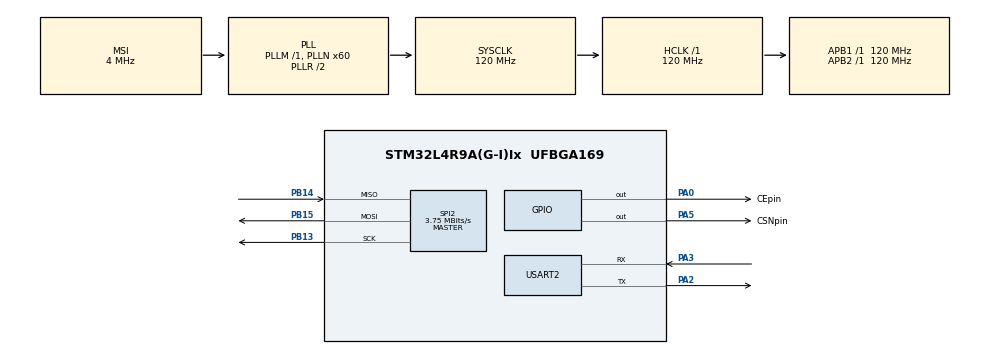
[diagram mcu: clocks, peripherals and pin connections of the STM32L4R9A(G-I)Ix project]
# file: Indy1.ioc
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Mcu.Family=STM32L4
Mcu.Name=STM32L4R9A(G-I)Ix
Mcu.Package=UFBGA169
NVIC.PriorityGroup=NVIC_PRIORITYGROUP_4
PA0.GPIO_Label=CEpin
PA0.Signal=GPIO_Output
PA2.Mode=Asynchronous
PA2.Signal=USART2_TX
PA3.Mode=Asynchronous
PA3.Signal=USART2_RX
PA5.GPIO_Label=CSNpin
PA5.Signal=GPIO_Output
PB13.Mode=Full_Duplex_Master
PB13.Signal=SPI2_SCK
PB14.Mode=Full_Duplex_Master
PB14.Signal=SPI2_MISO
PB15.Mode=Full_Duplex_Master
PB15.Signal=SPI2_MOSI
ProjectManager.HeapSize=0x200
ProjectManager.StackSize=0x400
ProjectManager.TargetToolchain=STM32CubeIDE
RCC.ADCFreq_Value=32000000
RCC.AHBFreq_Value=120000000
RCC.APB1Freq_Value=120000000
RCC.APB1TimFreq_Value=120000000
RCC.APB2Freq_Value=120000000
RCC.APB2TimFreq_Value=120000000
RCC.CK48CLockSelection=RCC_USBCLKSOURCE_HSI48
RCC.CortexFreq_Value=120000000
RCC.HCLKFreq_Value=120000000
RCC.HSE_VALUE=16000000
RCC.HSI48_VALUE=48000000
RCC.HSI_VALUE=16000000
RCC.LSE_VALUE=32768
RCC.MSI_VALUE=4000000
RCC.PLLDSINDIV=32
RCC.PLLN=60
RCC.PLLP=RCC_PLLP_DIV5
RCC.PLLSAI1N=16
RCC.SYSCLKFreq_VALUE=120000000
RCC.SYSCLKSource=RCC_SYSCLKSOURCE_PLLCLK
RCC.USBFreq_Value=48000000
RCC.VCOOutputFreq_Value=240000000
SPI2.BaudRatePrescaler=SPI_BAUDRATEPRESCALER_32
SPI2.CalculateBaudRate=3.75 MBits/s
SPI2.DataSize=SPI_DATASIZE_8BIT
SPI2.Direction=SPI_DIRECTION_2LINES
SPI2.Mode=SPI_MODE_MASTER
SPI2.VirtualType=VM_MASTER
STMicroelectronics.X-CUBE-TOUCHGFX.4.13.0.ApplicationCcGraphicsJjApplication=TouchGFXOoGenerator
USART2.VirtualMode-Asynchronous=VM_ASYNC
board=STM32L4R9I-DISCO

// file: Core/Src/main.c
/* USER CODE BEGIN Header */
/**
  ******************************************************************************
  * @file           : main.c
  * @brief          : Main program body
  ******************************************************************************
  * @attention
  *
  * <h2><center>&copy; Copyright (c) 2020 STMicroelectronics.
  * All rights reserved.</center></h2>
  *
  * This software component is licensed by ST under BSD 3-Clause license,
  * the "License"; You may not use this file except in compliance with the
  * License. You may obtain a copy of the License at:
  *                        opensource.org/licenses/BSD-3-Clause
  *
  ******************************************************************************
  */
/* USER CODE END Header */

#include "main.h"

/* USER CODE BEGIN Includes */
#include "MY_NRF24.h"
#include "Mousejack.h"
#include "stm32l4xx_hal.h"
/* USER CODE END Includes */

/* USER CODE BEGIN PD */
uint8_t myTxData[13] = "Hello World\r\n";
/* USER CODE END PD */

void SystemClock_Config(void);
static void MX_GPIO_Init(void);
static void MX_SPI2_Init(void);
static void MX_USART2_UART_Init(void);

int main(void)
{

  /* MCU Configuration--------------------------------------------------------*/

  /* Reset of all peripherals, Initializes the Flash interface and the Systick. */
  HAL_Init();

  /* Configure the system clock */
  SystemClock_Config();

  /* Initialize all configured peripherals */
  MX_GPIO_Init();
  MX_SPI2_Init();
  MX_USART2_UART_Init();
  /* USER CODE BEGIN 2 */

  //NRF24_begin(CEpin_GPIO_Port, CSNpin_Pin, CEpin_Pin, hspi2);
  nrf24_DebugUART_Init(huart2);
  while(1){
	  loop();
  }
  /* USER CODE END 2 */

  /* Infinite loop */
  /* USER CODE BEGIN WHILE */
  if(NRF24_Check()){
	  //Success!
	  printRadioSettings();
  }//end if
  else{
	  //Failure
	  while(1){};
  }//end else*/
  while (1)
  {
    /* USER CODE END WHILE */

    /* USER CODE BEGIN 3 */
//	  char msg[100];
//	  sprintf(msg, "Hello, world please work\r\n");
	  //HAL_UART_Transmit(&nrf24_huart, (uint8_t *)uartTxBuf, strlen(uartTxBuf), 10);
//	  HAL_UART_Transmit(&huart2, (uint8_t *)msg, strlen(msg), 10);
//	  HAL_Delay(300);

  }
  /* USER CODE END 3 */
}

void SystemClock_Config(void)
{
  RCC_OscInitTypeDef RCC_OscInitStruct = {0};
  RCC_ClkInitTypeDef RCC_ClkInitStruct = {0};
  RCC_PeriphCLKInitTypeDef PeriphClkInit = {0};

  /** Configure the main internal regulator output voltage
  */
  if (HAL_PWREx_ControlVoltageScaling(PWR_REGULATOR_VOLTAGE_SCALE1_BOOST) != HAL_OK)
  {
    Error_Handler();
  }
  /** Initializes the CPU, AHB and APB busses clocks
  */
  RCC_OscInitStruct.OscillatorType = RCC_OSCILLATORTYPE_MSI;
  RCC_OscInitStruct.MSIState = RCC_MSI_ON;
  RCC_OscInitStruct.MSICalibrationValue = 0;
  RCC_OscInitStruct.MSIClockRange = RCC_MSIRANGE_6;
  RCC_OscInitStruct.PLL.PLLState = RCC_PLL_ON;
  RCC_OscInitStruct.PLL.PLLSource = RCC_PLLSOURCE_MSI;
  RCC_OscInitStruct.PLL.PLLM = 1;
  RCC_OscInitStruct.PLL.PLLN = 60;
  RCC_OscInitStruct.PLL.PLLP = RCC_PLLP_DIV5;
  RCC_OscInitStruct.PLL.PLLQ = RCC_PLLQ_DIV2;
  RCC_OscInitStruct.PLL.PLLR = RCC_PLLR_DIV2;
  if (HAL_RCC_OscConfig(&RCC_OscInitStruct) != HAL_OK)
  {
    Error_Handler();
  }
  /** Initializes the CPU, AHB and APB busses clocks
  */
  RCC_ClkInitStruct.ClockType = RCC_CLOCKTYPE_HCLK|RCC_CLOCKTYPE_SYSCLK
                              |RCC_CLOCKTYPE_PCLK1|RCC_CLOCKTYPE_PCLK2;
  RCC_ClkInitStruct.SYSCLKSource = RCC_SYSCLKSOURCE_PLLCLK;
  RCC_ClkInitStruct.AHBCLKDivider = RCC_SYSCLK_DIV1;
  RCC_ClkInitStruct.APB1CLKDivider = RCC_HCLK_DIV1;
  RCC_ClkInitStruct.APB2CLKDivider = RCC_HCLK_DIV1;

  if (HAL_RCC_ClockConfig(&RCC_ClkInitStruct, FLASH_LATENCY_5) != HAL_OK)
  {
    Error_Handler();
  }
  PeriphClkInit.PeriphClockSelection = RCC_PERIPHCLK_USART2;
  PeriphClkInit.Usart2ClockSelection = RCC_USART2CLKSOURCE_PCLK1;
  if (HAL_RCCEx_PeriphCLKConfig(&PeriphClkInit) != HAL_OK)
  {
    Error_Handler();
  }
}

static void MX_SPI2_Init(void)
{

  /* SPI2 parameter configuration*/
  hspi2.Instance = SPI2;
  hspi2.Init.Mode = SPI_MODE_MASTER;
  hspi2.Init.Direction = SPI_DIRECTION_2LINES;
  hspi2.Init.DataSize = SPI_DATASIZE_8BIT;
  hspi2.Init.CLKPolarity = SPI_POLARITY_LOW;
  hspi2.Init.CLKPhase = SPI_PHASE_1EDGE;
  hspi2.Init.NSS = SPI_NSS_SOFT;
  hspi2.Init.BaudRatePrescaler = SPI_BAUDRATEPRESCALER_32;
  hspi2.Init.FirstBit = SPI_FIRSTBIT_MSB;
  hspi2.Init.TIMode = SPI_TIMODE_DISABLE;
  hspi2.Init.CRCCalculation = SPI_CRCCALCULATION_DISABLE;
  hspi2.Init.CRCPolynomial = 7;
  hspi2.Init.CRCLength = SPI_CRC_LENGTH_DATASIZE;
  hspi2.Init.NSSPMode = SPI_NSS_PULSE_ENABLE;
  if (HAL_SPI_Init(&hspi2) != HAL_OK)
  {
    Error_Handler();
  }

}

static void MX_USART2_UART_Init(void)
{

  huart2.Instance = USART2;
  huart2.Init.BaudRate = 115200;
  huart2.Init.WordLength = UART_WORDLENGTH_8B;
  huart2.Init.StopBits = UART_STOPBITS_1;
  huart2.Init.Parity = UART_PARITY_NONE;
  huart2.Init.Mode = UART_MODE_TX_RX;
  huart2.Init.HwFlowCtl = UART_HWCONTROL_NONE;
  huart2.Init.OverSampling = UART_OVERSAMPLING_16;
  huart2.Init.OneBitSampling = UART_ONE_BIT_SAMPLE_DISABLE;
  huart2.Init.ClockPrescaler = UART_PRESCALER_DIV1;
  huart2.AdvancedInit.AdvFeatureInit = UART_ADVFEATURE_NO_INIT;
  if (HAL_UART_Init(&huart2) != HAL_OK)
  {
    Error_Handler();
  }
  if (HAL_UARTEx_SetTxFifoThreshold(&huart2, UART_TXFIFO_THRESHOLD_1_8) != HAL_OK)
  {
    Error_Handler();
  }
  if (HAL_UARTEx_SetRxFifoThreshold(&huart2, UART_RXFIFO_THRESHOLD_1_8) != HAL_OK)
  {
    Error_Handler();
  }
  if (HAL_UARTEx_DisableFifoMode(&huart2) != HAL_OK)
  {
    Error_Handler();
  }

}

static void MX_GPIO_Init(void)
{
  GPIO_InitTypeDef GPIO_InitStruct = {0};

  /* GPIO Ports Clock Enable */
  __HAL_RCC_GPIOA_CLK_ENABLE();
  __HAL_RCC_GPIOB_CLK_ENABLE();

  /*Configure GPIO pin Output Level */
  HAL_GPIO_WritePin(GPIOA, CEpin_Pin|CSNpin_Pin, GPIO_PIN_RESET);

  /*Configure GPIO pins : CEpin_Pin CSNpin_Pin */
  GPIO_InitStruct.Pin = CEpin_Pin|CSNpin_Pin;
  GPIO_InitStruct.Mode = GPIO_MODE_OUTPUT_PP;
  GPIO_InitStruct.Pull = GPIO_NOPULL;
  GPIO_InitStruct.Speed = GPIO_SPEED_FREQ_LOW;
  HAL_GPIO_Init(GPIOA, &GPIO_InitStruct);

}

void Error_Handler(void)
{
}

/************************ (C) COPYRIGHT STMicroelectronics *****END OF FILE****/
